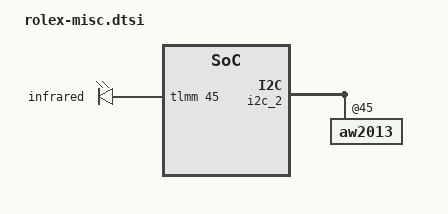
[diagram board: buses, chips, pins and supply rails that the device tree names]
/*
 * Copyright (c) 2016, The Linux Foundation. All rights reserved.
 * Copyright (C) 2018 XiaoMi, Inc.
 *
 * This program is free software; you can redistribute it and/or modify
 * it under the terms of the GNU General Public License version 2 and
 * only version 2 as published by the Free Software Foundation.
 *
 * This program is distributed in the hope that it will be useful,
 * but WITHOUT ANY WARRANTY; without even the implied warranty of
 * MERCHANTABILITY or FITNESS FOR A PARTICULAR PURPOSE.  See the
 * GNU General Public License for more details.
 */

&soc {
	gpio-leds {
		compatible = "gpio-leds";
		status = "okay";
		pinctrl-names = "default";
		pinctrl-0 = <&gpio_led_off>;

			infred {
			gpios = <&tlmm 45 0>;
			label = "infrared";
			linux,default-trigger = "infra-red";
			default-state = "off";
			retain-state-suspended;
		};
	};
};

&i2c_2  {
	aw2013@45 {
		aw2013,red {
			aw2013,name = "red";
			aw2013,id = <0>;
			aw2013,max-brightness = <255>;
			aw2013,max-current = <1>;
			aw2013,rise-time-ms = <2>;
			aw2013,hold-time-ms = <1>;
			aw2013,fall-time-ms = <2>;
			aw2013,off-time-ms = <1>;
		};
		aw2013,green {
			aw2013,name = "green";
			aw2013,id = <1>;
			aw2013,max-brightness = <255>;
			aw2013,max-current = <1>;
			aw2013,rise-time-ms = <2>;
			aw2013,hold-time-ms = <1>;
			aw2013,fall-time-ms = <2>;
			aw2013,off-time-ms = <1>;
		};
		aw2013,blue {
			aw2013,name = "blue";
			aw2013,id = <2>;
			aw2013,max-brightness = <255>;
			aw2013,max-current = <1>;
			aw2013,rise-time-ms = <2>;
			aw2013,hold-time-ms = <1>;
			aw2013,fall-time-ms = <2>;
			aw2013,off-time-ms = <1>;
		};
	};
};
